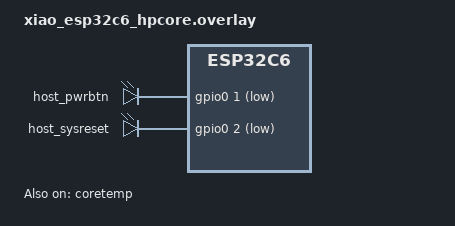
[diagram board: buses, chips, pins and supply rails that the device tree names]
/*
 * SPDX-FileCopyrightText: © 2025-2026 Tenstorrent USA, Inc.
 * SPDX-License-Identifier: Apache-2.0
 *
 * Seeed Studio XIAO ESP32-C6 port.
 *
 * The BMC console / shell is the SoC's built-in USB Serial/JTAG (the
 * XIAO's USB-C connector); the board DTS already routes
 * zephyr,console + zephyr,shell-uart there. The host serial bridge
 * uses UART0 on the default D6 and D7 pins..
 *
 *   D1 = GPIO1  = PWRBTN#   (open-drain, active-low)
 *   D2 = GPIO2  = SYSRESET# (open-drain, active-low)
 *   D6 = GPIO16 = UART0 TX (out to host RX)
 *   D7 = GPIO17 = UART0 RX (in from host TX)
 *   Must connect common GND with the host board.
 *
 * /jtag node omitted -> CONFIG_JTAG auto-disabled via dt_path_enabled().
 */

#include <zephyr/dt-bindings/gpio/gpio.h>
#include <zephyr/dt-bindings/pinctrl/esp-pinctrl-common.h>
#include <zephyr/dt-bindings/pinctrl/esp32c6-pinctrl.h>
#include <zephyr/dt-bindings/pinctrl/esp32c6-gpio-sigmap.h>

/ {
	host_power {
		compatible = "gpio-leds";

		/*
		 * Host power button and system reset. Open-drain + active-low:
		 * the ESP32 only ever sinks current; the un-asserted level is
		 * set by the host (e.g. K3 internal pull-up) or, with no host
		 * connected, by the ESP32 internal pull-up that GPIO_PULL_UP
		 * enables here -- so the line idles high either way, including
		 * for bench probing with an oscilloscope. host_pwrbtn is pulsed
		 * by power.c when CONFIG_APP_HOST_POWER_PULSE=y. host_sysreset
		 * is pulsed by `reset` (power_reset())
		 * for ~1 s.
		 */
		host_pwrbtn: host_pwrbtn {
			gpios = <&gpio0 1 (GPIO_ACTIVE_LOW | GPIO_OPEN_DRAIN | GPIO_PULL_UP)>;
		};
		host_sysreset: host_sysreset {
			gpios = <&gpio0 2 (GPIO_ACTIVE_LOW | GPIO_OPEN_DRAIN | GPIO_PULL_UP)>;
		};
	};

	aliases {
		host-console-uart = &uart0;
		power-gpio-1 = &host_pwrbtn;
		reset-gpio-1 = &host_sysreset;
		status-led = &yellow_led;
		die-temp = &coretemp;
	};
};

&coretemp {
    status = "okay";
};
